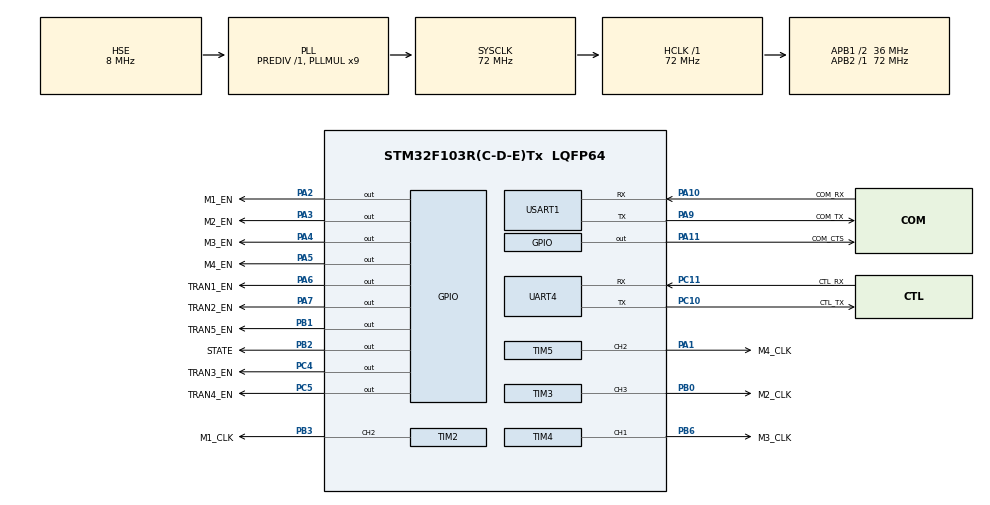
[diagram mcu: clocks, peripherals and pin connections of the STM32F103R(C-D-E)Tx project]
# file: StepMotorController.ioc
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Dma.Request0=USART1_RX
Dma.Request1=USART1_TX
Dma.Request2=TIM3_CH4/UP
Dma.Request3=TIM2_UP
Dma.Request4=TIM4_UP
Dma.Request5=TIM5_CH3/UP
Dma.Request6=UART4_RX
Dma.Request7=UART4_TX
Dma.TIM2_UP.3.Direction=DMA_MEMORY_TO_PERIPH
Dma.TIM2_UP.3.Instance=DMA1_Channel2
Dma.TIM2_UP.3.MemDataAlignment=DMA_MDATAALIGN_HALFWORD
Dma.TIM2_UP.3.MemInc=DMA_MINC_ENABLE
Dma.TIM2_UP.3.Mode=DMA_NORMAL
Dma.TIM2_UP.3.PeriphDataAlignment=DMA_PDATAALIGN_HALFWORD
Dma.TIM2_UP.3.PeriphInc=DMA_PINC_DISABLE
Dma.TIM2_UP.3.Priority=DMA_PRIORITY_VERY_HIGH
Dma.TIM3_CH4/UP.2.Direction=DMA_MEMORY_TO_PERIPH
Dma.TIM3_CH4/UP.2.Instance=DMA1_Channel3
Dma.TIM3_CH4/UP.2.MemDataAlignment=DMA_MDATAALIGN_HALFWORD
Dma.TIM3_CH4/UP.2.MemInc=DMA_MINC_ENABLE
Dma.TIM3_CH4/UP.2.Mode=DMA_NORMAL
Dma.TIM3_CH4/UP.2.PeriphDataAlignment=DMA_PDATAALIGN_HALFWORD
Dma.TIM3_CH4/UP.2.PeriphInc=DMA_PINC_DISABLE
Dma.TIM3_CH4/UP.2.Priority=DMA_PRIORITY_VERY_HIGH
Dma.TIM4_UP.4.Direction=DMA_MEMORY_TO_PERIPH
Dma.TIM4_UP.4.Instance=DMA1_Channel7
Dma.TIM4_UP.4.MemDataAlignment=DMA_MDATAALIGN_HALFWORD
Dma.TIM4_UP.4.MemInc=DMA_MINC_ENABLE
Dma.TIM4_UP.4.Mode=DMA_NORMAL
Dma.TIM4_UP.4.PeriphDataAlignment=DMA_PDATAALIGN_HALFWORD
Dma.TIM4_UP.4.PeriphInc=DMA_PINC_DISABLE
Dma.TIM4_UP.4.Priority=DMA_PRIORITY_VERY_HIGH
Dma.TIM5_CH3/UP.5.Direction=DMA_MEMORY_TO_PERIPH
Dma.TIM5_CH3/UP.5.Instance=DMA2_Channel2
Dma.TIM5_CH3/UP.5.MemDataAlignment=DMA_MDATAALIGN_HALFWORD
Dma.TIM5_CH3/UP.5.MemInc=DMA_MINC_ENABLE
Dma.TIM5_CH3/UP.5.Mode=DMA_NORMAL
Dma.TIM5_CH3/UP.5.PeriphDataAlignment=DMA_PDATAALIGN_HALFWORD
Dma.TIM5_CH3/UP.5.PeriphInc=DMA_PINC_DISABLE
Dma.TIM5_CH3/UP.5.Priority=DMA_PRIORITY_VERY_HIGH
Dma.UART4_RX.6.Direction=DMA_PERIPH_TO_MEMORY
Dma.UART4_RX.6.Instance=DMA2_Channel3
Dma.UART4_RX.6.MemDataAlignment=DMA_MDATAALIGN_BYTE
Dma.UART4_RX.6.MemInc=DMA_MINC_ENABLE
Dma.UART4_RX.6.Mode=DMA_NORMAL
Dma.UART4_RX.6.PeriphDataAlignment=DMA_PDATAALIGN_BYTE
Dma.UART4_RX.6.PeriphInc=DMA_PINC_DISABLE
Dma.UART4_RX.6.Priority=DMA_PRIORITY_LOW
Dma.UART4_TX.7.Direction=DMA_MEMORY_TO_PERIPH
Dma.UART4_TX.7.Instance=DMA2_Channel5
Dma.UART4_TX.7.MemDataAlignment=DMA_MDATAALIGN_BYTE
Dma.UART4_TX.7.MemInc=DMA_MINC_ENABLE
Dma.UART4_TX.7.Mode=DMA_NORMAL
Dma.UART4_TX.7.PeriphDataAlignment=DMA_PDATAALIGN_BYTE
Dma.UART4_TX.7.PeriphInc=DMA_PINC_DISABLE
Dma.UART4_TX.7.Priority=DMA_PRIORITY_LOW
Dma.USART1_RX.0.Direction=DMA_PERIPH_TO_MEMORY
Dma.USART1_RX.0.Instance=DMA1_Channel5
Dma.USART1_RX.0.MemDataAlignment=DMA_MDATAALIGN_BYTE
Dma.USART1_RX.0.MemInc=DMA_MINC_ENABLE
Dma.USART1_RX.0.Mode=DMA_NORMAL
Dma.USART1_RX.0.PeriphDataAlignment=DMA_PDATAALIGN_BYTE
Dma.USART1_RX.0.PeriphInc=DMA_PINC_DISABLE
Dma.USART1_RX.0.Priority=DMA_PRIORITY_LOW
Dma.USART1_TX.1.Direction=DMA_MEMORY_TO_PERIPH
Dma.USART1_TX.1.Instance=DMA1_Channel4
Dma.USART1_TX.1.MemDataAlignment=DMA_MDATAALIGN_BYTE
Dma.USART1_TX.1.MemInc=DMA_MINC_ENABLE
Dma.USART1_TX.1.Mode=DMA_NORMAL
Dma.USART1_TX.1.PeriphDataAlignment=DMA_PDATAALIGN_BYTE
Dma.USART1_TX.1.PeriphInc=DMA_PINC_DISABLE
Dma.USART1_TX.1.Priority=DMA_PRIORITY_LOW
IWDG.Prescaler=IWDG_PRESCALER_64
IWDG.Reload=625
Mcu.Family=STM32F1
Mcu.Name=STM32F103R(C-D-E)Tx
Mcu.Package=LQFP64
NVIC.DMA1_Channel2_IRQn=true\:5\:0\:true\:false\:true\:false\:true\:true
NVIC.DMA1_Channel3_IRQn=true\:5\:0\:true\:false\:true\:false\:true\:true
NVIC.DMA1_Channel4_IRQn=true\:5\:0\:true\:false\:true\:false\:true\:true
NVIC.DMA1_Channel5_IRQn=true\:5\:0\:true\:false\:true\:false\:true\:true
NVIC.DMA1_Channel7_IRQn=true\:5\:0\:true\:false\:true\:false\:true\:true
NVIC.DMA2_Channel2_IRQn=true\:5\:0\:true\:false\:true\:false\:true\:true
NVIC.DMA2_Channel3_IRQn=true\:0\:0\:true\:false\:true\:false\:true\:true
NVIC.DMA2_Channel4_5_IRQn=true\:0\:0\:false\:false\:true\:false\:true\:true
NVIC.PriorityGroup=NVIC_PRIORITYGROUP_4
NVIC.TIM6_IRQn=true\:1\:0\:true\:false\:true\:true\:true\:true
NVIC.UART4_IRQn=true\:0\:0\:true\:false\:true\:true\:true\:true
NVIC.USART1_IRQn=true\:1\:0\:true\:false\:true\:true\:true\:true
PA1.GPIO_Label=M4_CLK
PA1.Signal=S_TIM5_CH2
PA10.GPIO_Label=COM_RX
PA10.GPIO_PuPd=GPIO_PULLUP
PA10.Mode=Asynchronous
PA10.Signal=USART1_RX
PA11.GPIO_Label=COM_CTS
PA11.Signal=GPIO_Output
PA13.GPIO_Label=SWDIO
PA13.Mode=Serial_Wire
PA13.Signal=SYS_JTMS-SWDIO
PA14.GPIO_Label=SWCLK
PA14.Mode=Serial_Wire
PA14.Signal=SYS_JTCK-SWCLK
PA2.GPIO_Label=M1_EN
PA2.Signal=GPIO_Output
PA3.GPIO_Label=M2_EN
PA3.Signal=GPIO_Output
PA4.GPIO_Label=M3_EN
PA4.Signal=GPIO_Output
PA5.GPIO_Label=M4_EN
PA5.Signal=GPIO_Output
PA6.GPIO_Label=TRAN1_EN
PA6.PinState=GPIO_PIN_SET
PA6.Signal=GPIO_Output
PA7.GPIO_Label=TRAN2_EN
PA7.PinState=GPIO_PIN_SET
PA7.Signal=GPIO_Output
PA9.GPIO_Label=COM_TX
PA9.Mode=Asynchronous
PA9.Signal=USART1_TX
PB0.GPIO_Label=M2_CLK
PB0.Signal=S_TIM3_CH3
PB1.GPIO_Label=TRAN5_EN
PB1.PinState=GPIO_PIN_SET
PB1.Signal=GPIO_Output
PB2.GPIO_Label=STATE
PB2.Signal=GPIO_Output
PB3.GPIO_Label=M1_CLK
PB3.Signal=S_TIM2_CH2
PB6.GPIO_Label=M3_CLK
PB6.Signal=S_TIM4_CH1
PC10.GPIO_Label=CTL_TX
PC10.Mode=Asynchronous
PC10.Signal=UART4_TX
PC11.GPIO_Label=CTL_RX
PC11.GPIO_PuPd=GPIO_PULLUP
PC11.Mode=Asynchronous
PC11.Signal=UART4_RX
PC4.GPIO_Label=TRAN3_EN
PC4.PinState=GPIO_PIN_SET
PC4.Signal=GPIO_Output
PC5.GPIO_Label=TRAN4_EN
PC5.PinState=GPIO_PIN_SET
PC5.Signal=GPIO_Output
PD0-OSC_IN.Mode=HSE-External-Oscillator
PD0-OSC_IN.Signal=RCC_OSC_IN
PD1-OSC_OUT.Mode=HSE-External-Oscillator
PD1-OSC_OUT.Signal=RCC_OSC_OUT
ProjectManager.HeapSize=0x400
ProjectManager.StackSize=0x400
ProjectManager.TargetToolchain=MDK-ARM V5.32
RCC.AHBFreq_Value=72000000
RCC.APB1CLKDivider=RCC_HCLK_DIV2
RCC.APB1Freq_Value=36000000
RCC.APB1TimFreq_Value=72000000
RCC.APB2Freq_Value=72000000
RCC.APB2TimFreq_Value=72000000
RCC.HCLKFreq_Value=72000000
RCC.PLLMUL=RCC_PLL_MUL9
RCC.PLLSourceVirtual=RCC_PLLSOURCE_HSE
RCC.SYSCLKFreq_VALUE=72000000
RCC.SYSCLKSource=RCC_SYSCLKSOURCE_PLLCLK
RCC.USBFreq_Value=72000000
SH.S_TIM2_CH2.0=TIM2_CH2,PWM Generation2 CH2
SH.S_TIM3_CH3.0=TIM3_CH3,PWM Generation3 CH3
SH.S_TIM4_CH1.0=TIM4_CH1,PWM Generation1 CH1
SH.S_TIM5_CH2.0=TIM5_CH2,PWM Generation2 CH2
TIM2.AutoReloadPreload=TIM_AUTORELOAD_PRELOAD_ENABLE
TIM2.Channel-PWM\ Generation2\ CH2=TIM_CHANNEL_2
TIM2.Period=0
TIM2.Prescaler=71
TIM2.TIM_MasterOutputTrigger=TIM_TRGO_RESET
TIM3.AutoReloadPreload=TIM_AUTORELOAD_PRELOAD_ENABLE
TIM3.Channel-PWM\ Generation3\ CH3=TIM_CHANNEL_3
TIM3.TIM_MasterOutputTrigger=TIM_TRGO_RESET
TIM4.Channel-PWM\ Generation1\ CH1=TIM_CHANNEL_1
TIM4.TIM_MasterOutputTrigger=TIM_TRGO_RESET
TIM5.Channel-PWM\ Generation2\ CH2=TIM_CHANNEL_2
TIM5.TIM_MasterOutputTrigger=TIM_TRGO_RESET
TIM6.Period=499
TIM6.Prescaler=71
UART4.VirtualMode=Asynchronous
USART1.VirtualMode=VM_ASYNC
VP_IWDG_VS_IWDG.Mode=IWDG_Activate
VP_TIM2_VS_ClockSourceINT.Mode=Internal
VP_TIM3_VS_ClockSourceINT.Mode=Internal
VP_TIM4_VS_ClockSourceINT.Mode=Internal
VP_TIM5_VS_ClockSourceINT.Mode=Internal
VP_TIM6_VS_ClockSourceINT.Mode=Enable_Timer
board=custom

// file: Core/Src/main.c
/* USER CODE BEGIN Header */
/**
  ******************************************************************************
  * @file           : main.c
  * @brief          : Main program body
  ******************************************************************************
  * @attention
  *
  * Copyright (c) 2023 STMicroelectronics.
  * All rights reserved.
  *
  * This software is licensed under terms that can be found in the LICENSE file
  * in the root directory of this software component.
  * If no LICENSE file comes with this software, it is provided AS-IS.
  *
  ******************************************************************************
  */
/* USER CODE END Header */
#include "main.h"
#include "dma.h"
#include "iwdg.h"
#include "tim.h"
#include "usart.h"
#include "gpio.h"

/* USER CODE BEGIN Includes */
#include "control.h"
/* USER CODE END Includes */

void SystemClock_Config(void);

int main(void)
{

  /* MCU Configuration--------------------------------------------------------*/

  /* Reset of all peripherals, Initializes the Flash interface and the Systick. */
  HAL_Init();

  /* Configure the system clock */
  SystemClock_Config();

  /* Initialize all configured peripherals */
  MX_GPIO_Init();
  MX_DMA_Init();
  MX_IWDG_Init();
  MX_TIM2_Init();
  MX_TIM3_Init();
  MX_TIM4_Init();
  MX_TIM5_Init();
  MX_TIM6_Init();
  MX_UART4_Init();
  MX_USART1_UART_Init();
  /* USER CODE BEGIN 2 */
	control_init();
	control_start();
  /* USER CODE END 2 */

  /* Infinite loop */
  /* USER CODE BEGIN WHILE */
  while (1)
  {
		HAL_IWDG_Refresh(&hiwdg);
		HAL_Delay(1);
    /* USER CODE END WHILE */

  }
}

void SystemClock_Config(void)
{
  RCC_OscInitTypeDef RCC_OscInitStruct = {0};
  RCC_ClkInitTypeDef RCC_ClkInitStruct = {0};

  /** Initializes the RCC Oscillators according to the specified parameters
  * in the RCC_OscInitTypeDef structure.
  */
  RCC_OscInitStruct.OscillatorType = RCC_OSCILLATORTYPE_LSI|RCC_OSCILLATORTYPE_HSE;
  RCC_OscInitStruct.HSEState = RCC_HSE_ON;
  RCC_OscInitStruct.HSEPredivValue = RCC_HSE_PREDIV_DIV1;
  RCC_OscInitStruct.HSIState = RCC_HSI_ON;
  RCC_OscInitStruct.LSIState = RCC_LSI_ON;
  RCC_OscInitStruct.PLL.PLLState = RCC_PLL_ON;
  RCC_OscInitStruct.PLL.PLLSource = RCC_PLLSOURCE_HSE;
  RCC_OscInitStruct.PLL.PLLMUL = RCC_PLL_MUL9;
  if (HAL_RCC_OscConfig(&RCC_OscInitStruct) != HAL_OK)
  {
    Error_Handler();
  }

  /** Initializes the CPU, AHB and APB buses clocks
  */
  RCC_ClkInitStruct.ClockType = RCC_CLOCKTYPE_HCLK|RCC_CLOCKTYPE_SYSCLK
                              |RCC_CLOCKTYPE_PCLK1|RCC_CLOCKTYPE_PCLK2;
  RCC_ClkInitStruct.SYSCLKSource = RCC_SYSCLKSOURCE_PLLCLK;
  RCC_ClkInitStruct.AHBCLKDivider = RCC_SYSCLK_DIV1;
  RCC_ClkInitStruct.APB1CLKDivider = RCC_HCLK_DIV2;
  RCC_ClkInitStruct.APB2CLKDivider = RCC_HCLK_DIV1;

  if (HAL_RCC_ClockConfig(&RCC_ClkInitStruct, FLASH_LATENCY_2) != HAL_OK)
  {
    Error_Handler();
  }
}

void Error_Handler(void)
{
  __disable_irq();
  while (1)
  {
  }
}
